AUTOSAR XML (schema 4-2-2)
package /STELLANTIS/EPT/ASWCs
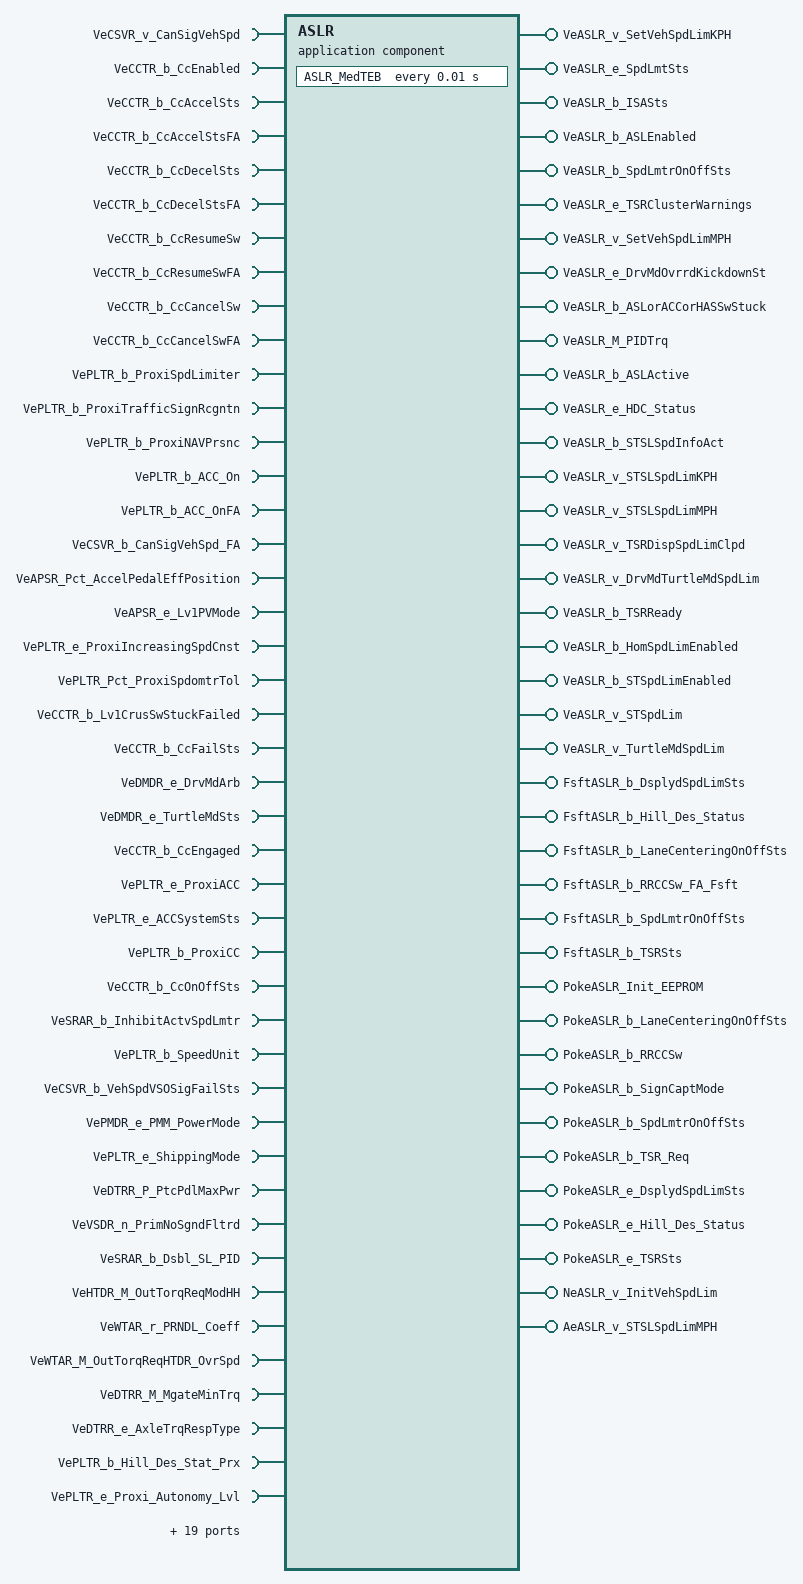
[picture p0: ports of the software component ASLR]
  application sw component type ASLR
    60 x require port:
      VeCSVR_v_CanSigVehSpd: variation-point={short-label=vpVeCSVR_v_CanSigVehSpd, sw-syscond=1}, nonqueued-receiver-com-spec{data-element=Value, init-value=0}, required-interface=VeCSVR_v_CanSigVehSpd
      VeCCTR_b_CcEnabled: variation-point={short-label=vpVeCCTR_b_CcEnabled, sw-syscond=1}, nonqueued-receiver-com-spec{data-element=Value, init-value=0}, required-interface=VeCCTR_b_CcEnabled
      VeCCTR_b_CcAccelSts: variation-point={short-label=vpVeCCTR_b_CcAccelSts, sw-syscond=1}, nonqueued-receiver-com-spec{data-element=Value, init-value=0}, required-interface=VeCCTR_b_CcAccelSts
      VeCCTR_b_CcAccelStsFA: variation-point={short-label=vpVeCCTR_b_CcAccelStsFA, sw-syscond=1}, nonqueued-receiver-com-spec{data-element=Value, init-value=0}, required-interface=VeCCTR_b_CcAccelStsFA
      VeCCTR_b_CcDecelSts: variation-point={short-label=vpVeCCTR_b_CcDecelSts, sw-syscond=1}, nonqueued-receiver-com-spec{data-element=Value, init-value=0}, required-interface=VeCCTR_b_CcDecelSts
      VeCCTR_b_CcDecelStsFA: variation-point={short-label=vpVeCCTR_b_CcDecelStsFA, sw-syscond=1}, nonqueued-receiver-com-spec{data-element=Value, init-value=0}, required-interface=VeCCTR_b_CcDecelStsFA
      VeCCTR_b_CcResumeSw: variation-point={short-label=vpVeCCTR_b_CcResumeSw, sw-syscond=1}, nonqueued-receiver-com-spec{data-element=Value, init-value=0}, required-interface=VeCCTR_b_CcResumeSw
      VeCCTR_b_CcResumeSwFA: variation-point={short-label=vpVeCCTR_b_CcResumeSwFA, sw-syscond=1}, nonqueued-receiver-com-spec{data-element=Value, init-value=0}, required-interface=VeCCTR_b_CcResumeSwFA
      VeCCTR_b_CcCancelSw: variation-point={short-label=vpVeCCTR_b_CcCancelSw, sw-syscond=1}, nonqueued-receiver-com-spec{data-element=Value, init-value=0}, required-interface=VeCCTR_b_CcCancelSw
      VeCCTR_b_CcCancelSwFA: variation-point={short-label=vpVeCCTR_b_CcCancelSwFA, sw-syscond=1}, nonqueued-receiver-com-spec{data-element=Value, init-value=0}, required-interface=VeCCTR_b_CcCancelSwFA
      VePLTR_b_ProxiSpdLimiter: variation-point={short-label=vpVePLTR_b_ProxiSpdLimiter, sw-syscond=1}, nonqueued-receiver-com-spec{data-element=Value, init-value=0}, required-interface=VePLTR_b_ProxiSpdLimiter
      VePLTR_b_ProxiTrafficSignRcgntn: variation-point={short-label=vpVePLTR_b_ProxiTrafficSignRcgntn, sw-syscond=1}, nonqueued-receiver-com-spec{data-element=Value, init-value=0}, required-interface=VePLTR_b_ProxiTrafficSignRcgntn
      VePLTR_b_ProxiNAVPrsnc: variation-point={short-label=vpVePLTR_b_ProxiNAVPrsnc, sw-syscond=1}, nonqueued-receiver-com-spec{data-element=Value, init-value=0}, required-interface=VePLTR_b_ProxiNAVPrsnc
      VePLTR_b_ACC_On: variation-point={short-label=vpVePLTR_b_ACC_On, sw-syscond=1}, nonqueued-receiver-com-spec{data-element=Value, init-value=0}, required-interface=VePLTR_b_ACC_On
      VePLTR_b_ACC_OnFA: variation-point={short-label=vpVePLTR_b_ACC_OnFA, sw-syscond=1}, nonqueued-receiver-com-spec{data-element=Value, init-value=0}, required-interface=VePLTR_b_ACC_OnFA
      VeCSVR_b_CanSigVehSpd_FA: variation-point={short-label=vpVeCSVR_b_CanSigVehSpd_FA, sw-syscond=1}, nonqueued-receiver-com-spec{data-element=Value, init-value=0}, required-interface=VeCSVR_b_CanSigVehSpd_FA
      VeAPSR_Pct_AccelPedalEffPosition: variation-point={short-label=vpVeAPSR_Pct_AccelPedalEffPosition, sw-syscond=1}, nonqueued-receiver-com-spec{data-element=Value, init-value=0}, required-interface=VeAPSR_Pct_AccelPedalEffPosition
      VeAPSR_e_Lv1PVMode: variation-point={short-label=vpVeAPSR_e_Lv1PVMode, sw-syscond=1}, nonqueued-receiver-com-spec{data-element=Value, init-value=CeAPSR_e_LV1PVMode_NotValid}, required-interface=VeAPSR_e_Lv1PVMode
      VePLTR_e_ProxiIncreasingSpdCnst: variation-point={short-label=vpVePLTR_e_ProxiIncreasingSpdCnst, sw-syscond=1}, nonqueued-receiver-com-spec{data-element=Value, init-value=CePLTR_e_Increasing_0}, required-interface=VePLTR_e_ProxiIncreasingSpdCnst
      VePLTR_Pct_ProxiSpdomtrTol: variation-point={short-label=vpVePLTR_Pct_ProxiSpdomtrTol, sw-syscond=1}, nonqueued-receiver-com-spec{data-element=Value, init-value=0}, required-interface=VePLTR_Pct_ProxiSpdomtrTol
      VeCCTR_b_Lv1CrusSwStuckFailed: variation-point={short-label=vpVeCCTR_b_Lv1CrusSwStuckFailed, sw-syscond=1}, nonqueued-receiver-com-spec{data-element=Value, init-value=0}, required-interface=VeCCTR_b_Lv1CrusSwStuckFailed
      VeCCTR_b_CcFailSts: variation-point={short-label=vpVeCCTR_b_CcFailSts, sw-syscond=1}, nonqueued-receiver-com-spec{data-element=Value, init-value=0}, required-interface=VeCCTR_b_CcFailSts
      VeDMDR_e_DrvMdArb: variation-point={short-label=vpVeDMDR_e_DrvMdArb, sw-syscond=1}, nonqueued-receiver-com-spec{data-element=Value, init-value=CeDMDR_e_NoDrvMd}, required-interface=VeDMDR_e_DrvMdArb
      VeDMDR_e_TurtleMdSts: variation-point={short-label=vpVeDMDR_e_TurtleMdSts, sw-syscond=1}, nonqueued-receiver-com-spec{data-element=Value, init-value=CeDMDR_e_No_Turtle_Mode}, required-interface=VeDMDR_e_TurtleMdSts
      VeCCTR_b_CcEngaged: variation-point={short-label=vpVeCCTR_b_CcEngaged, sw-syscond=1}, nonqueued-receiver-com-spec{data-element=Value, init-value=0}, required-interface=VeCCTR_b_CcEngaged
      VePLTR_e_ProxiACC: variation-point={short-label=vpVePLTR_e_ProxiACC, sw-syscond=1}, nonqueued-receiver-com-spec{data-element=Value, init-value=CePLTR_e_ACC_Absent}, required-interface=VePLTR_e_ProxiACC
      VePLTR_e_ACCSystemSts: variation-point={short-label=vpVePLTR_e_ACCSystemSts, sw-syscond=1}, nonqueued-receiver-com-spec{data-element=Value, init-value=CePLTR_e_Off}, required-interface=VePLTR_e_ACCSystemSts
      VePLTR_b_ProxiCC: variation-point={short-label=vpVePLTR_b_ProxiCC, sw-syscond=1}, nonqueued-receiver-com-spec{data-element=Value, init-value=0}, required-interface=VePLTR_b_ProxiCC
      VeCCTR_b_CcOnOffSts: variation-point={short-label=vpVeCCTR_b_CcOnOffSts, sw-syscond=1}, nonqueued-receiver-com-spec{data-element=Value, init-value=0}, required-interface=VeCCTR_b_CcOnOffSts
      VeSRAR_b_InhibitActvSpdLmtr: variation-point={short-label=vpVeSRAR_b_InhibitActvSpdLmtr, sw-syscond=1}, nonqueued-receiver-com-spec{data-element=Value, init-value=0}, required-interface=VeSRAR_b_InhibitActvSpdLmtr
      VePLTR_b_SpeedUnit: variation-point={short-label=vpVePLTR_b_SpeedUnit, sw-syscond=1}, nonqueued-receiver-com-spec{data-element=Value, init-value=0}, required-interface=VePLTR_b_SpeedUnit
      VeCSVR_b_VehSpdVSOSigFailSts: variation-point={short-label=vpVeCSVR_b_VehSpdVSOSigFailSts, sw-syscond=1}, nonqueued-receiver-com-spec{data-element=Value, init-value=0}, required-interface=VeCSVR_b_VehSpdVSOSigFailSts
      VePMDR_e_PMM_PowerMode: variation-point={short-label=vpVePMDR_e_PMM_PowerMode, sw-syscond=1}, nonqueued-receiver-com-spec{data-element=Value, init-value=CePMDR_e_PowerMode_Off}, required-interface=VePMDR_e_PMM_PowerMode
      VePLTR_e_ShippingMode: variation-point={short-label=vpVePLTR_e_ShippingMode, sw-syscond=1}, nonqueued-receiver-com-spec{data-element=Value, init-value=CePLTR_e_ShipingMode_CUST_MD}, required-interface=VePLTR_e_ShippingMode
      VeDTRR_P_PtcPdlMaxPwr: variation-point={short-label=vpVeDTRR_P_PtcPdlMaxPwr, sw-syscond=1}, nonqueued-receiver-com-spec{data-element=Value, init-value=0}, required-interface=VeDTRR_P_PtcPdlMaxPwr
      VeVSDR_n_PrimNoSgndFltrd: variation-point={short-label=vpVeVSDR_n_PrimNoSgndFltrd, sw-syscond=1}, nonqueued-receiver-com-spec{data-element=Value, init-value=0}, required-interface=VeVSDR_n_PrimNoSgndFltrd
      VeSRAR_b_Dsbl_SL_PID: variation-point={short-label=vpVeSRAR_b_Dsbl_SL_PID, sw-syscond=1}, nonqueued-receiver-com-spec{data-element=Value, init-value=0}, required-interface=VeSRAR_b_Dsbl_SL_PID
      VeHTDR_M_OutTorqReqModHH: variation-point={short-label=vpVeHTDR_M_OutTorqReqModHH, sw-syscond=1}, nonqueued-receiver-com-spec{data-element=Value, init-value=0}, required-interface=VeHTDR_M_OutTorqReqModHH
      VeWTAR_r_PRNDL_Coeff: variation-point={short-label=vpVeWTAR_r_PRNDL_Coeff, sw-syscond=1}, nonqueued-receiver-com-spec{data-element=Value, init-value=0}, required-interface=VeWTAR_r_PRNDL_Coeff
      VeWTAR_M_OutTorqReqHTDR_OvrSpd: variation-point={short-label=vpVeWTAR_M_OutTorqReqHTDR_OvrSpd, sw-syscond=1}, nonqueued-receiver-com-spec{data-element=Value, init-value=0}, required-interface=VeWTAR_M_OutTorqReqHTDR_OvrSpd
      VeDTRR_M_MgateMinTrq: variation-point={short-label=vpVeDTRR_M_MgateMinTrq, sw-syscond=1}, nonqueued-receiver-com-spec{data-element=Value, init-value=0}, required-interface=VeDTRR_M_MgateMinTrq
      VeDTRR_e_AxleTrqRespType: variation-point={short-label=vpVeDTRR_e_AxleTrqRespType, sw-syscond=1}, nonqueued-receiver-com-spec{data-element=Value, init-value=CePTAR_e_Inactive}, required-interface=VeDTRR_e_AxleTrqRespType
      VePLTR_b_Hill_Des_Stat_Prx: variation-point={short-label=vpVePLTR_b_Hill_Des_Stat_Prx, sw-syscond=1}, nonqueued-receiver-com-spec{data-element=Value, init-value=0}, required-interface=VePLTR_b_Hill_Des_Stat_Prx
      VePLTR_e_Proxi_Autonomy_Lvl: variation-point={short-label=vpVePLTR_e_Proxi_Autonomy_Lvl, sw-syscond=1}, nonqueued-receiver-com-spec{data-element=Value, init-value=CePLTR_e_None_Level1}, required-interface=VePLTR_e_Proxi_Autonomy_Lvl
      VePLTR_e_Proxi_CC_Logic: variation-point={short-label=vpVePLTR_e_Proxi_CC_Logic, sw-syscond=1}, nonqueued-receiver-com-spec{data-element=Value, init-value=CePLTR_e_Logic1}, required-interface=VePLTR_e_Proxi_CC_Logic
      VeTMDR_e_TrrnMd: variation-point={short-label=vpVeTMDR_e_TrrnMd, sw-syscond=1}, nonqueued-receiver-com-spec{data-element=Value, init-value=CeTMDR_e_NotDefine}, required-interface=VeTMDR_e_TrrnMd
      VeCCTR_b_CcFailStsFA: variation-point={short-label=vpVeCCTR_b_CcFailStsFA, sw-syscond=1}, nonqueued-receiver-com-spec{data-element=Value, init-value=0}, required-interface=VeCCTR_b_CcFailStsFA
      VePLTR_b_ACCSystemSts_FA: variation-point={short-label=vpVePLTR_b_ACCSystemSts_FA, sw-syscond=1}, nonqueued-receiver-com-spec{data-element=Value, init-value=0}, required-interface=VePLTR_b_ACCSystemSts_FA
      VePLTR_b_SpeedUnit_FA: variation-point={short-label=vpVePLTR_b_SpeedUnit_FA, sw-syscond=1}, nonqueued-receiver-com-spec{data-element=Value, init-value=0}, required-interface=VePLTR_b_SpeedUnit_FA
      VeCSVR_v_VehSpdSigned: variation-point={short-label=vpVeCSVR_v_VehSpdSigned, sw-syscond=1}, nonqueued-receiver-com-spec{data-element=Value, init-value=0}, required-interface=VeCSVR_v_VehSpdSigned
      VeBSWR_e_SpdLimEEProgStatus: variation-point={short-label=vpVeBSWR_e_SpdLimEEProgStatus, sw-syscond=1}, nonqueued-receiver-com-spec{data-element=Value, init-value=0}, required-interface=VeBSWR_e_SpdLimEEProgStatus
      VePMDR_e_OperationalModeSts: variation-point={short-label=vpVePMDR_e_OperationalModeSts, sw-syscond=1}, nonqueued-receiver-com-spec{data-element=Value, init-value=CePMDR_e_Init}, required-interface=VePMDR_e_OperationalModeSts
      VeDTRR_e_RrAxleTrqRespType: variation-point={short-label=vpVeDTRR_e_RrAxleTrqRespType, sw-syscond=1}, nonqueued-receiver-com-spec{data-element=Value, init-value=CePTAR_e_Inactive}, required-interface=VeDTRR_e_RrAxleTrqRespType
      VePLTR_v_HomSpdLim: variation-point={short-label=vpVePLTR_v_HomSpdLim, sw-syscond=1}, nonqueued-receiver-com-spec{data-element=Value, init-value=0}, required-interface=VePLTR_v_HomSpdLim
      VePLTR_b_HDCEnabledCAN: variation-point={short-label=vpVePLTR_b_HDCEnabledCAN, sw-syscond=1}, nonqueued-receiver-com-spec{data-element=Value, init-value=0}, required-interface=VePLTR_b_HDCEnabledCAN
      VePLTR_e_VehCategory: variation-point={short-label=vpVePLTR_e_VehCategory, sw-syscond=1}, nonqueued-receiver-com-spec{data-element=Value, init-value=CePLTR_e_Category_M1}, required-interface=VePLTR_e_VehCategory
      VePLTR_b_RRCCPROXI: variation-point={short-label=vpVePLTR_b_RRCCPROXI, sw-syscond=1}, nonqueued-receiver-com-spec{data-element=Value, init-value=0}, required-interface=VePLTR_b_RRCCPROXI
      VeTMDR_e_PropulsionMd: variation-point={short-label=vpVeTMDR_e_PropulsionMd, sw-syscond=1}, nonqueued-receiver-com-spec{data-element=Value, init-value=CeTMDR_e_NotDefine}, required-interface=VeTMDR_e_PropulsionMd
      VeDCAB_v_STSLSpdLimMPH_DidWrite: nonqueued-receiver-com-spec{data-element=Value, init-value=0}, required-interface=VeDCAB_v_STSLSpdLimMPH_DidWrite
      VeGRAR_b_DisableASL: variation-point={short-label=vpVeGRAR_b_DisableASL, sw-syscond=1}, nonqueued-receiver-com-spec{data-element=Value, init-value=0}, required-interface=VeGRAR_b_DisableASL
    37 x provide port:
      VeASLR_v_SetVehSpdLimKPH: nonqueued-sender-com-spec{data-element=Value, init-value=0}, provided-interface=VeASLR_v_SetVehSpdLimKPH
      VeASLR_e_SpdLmtSts: nonqueued-sender-com-spec{data-element=Value, init-value=0}, provided-interface=VeASLR_e_SpdLmtSts
      VeASLR_b_ISASts: nonqueued-sender-com-spec{data-element=Value, init-value=0}, provided-interface=VeASLR_b_ISASts
      VeASLR_b_ASLEnabled: nonqueued-sender-com-spec{data-element=Value, init-value=0}, provided-interface=VeASLR_b_ASLEnabled
      VeASLR_b_SpdLmtrOnOffSts: nonqueued-sender-com-spec{data-element=Value, init-value=0}, provided-interface=VeASLR_b_SpdLmtrOnOffSts
      VeASLR_e_TSRClusterWarnings: nonqueued-sender-com-spec{data-element=Value, init-value=0}, provided-interface=VeASLR_e_TSRClusterWarnings
      VeASLR_v_SetVehSpdLimMPH: nonqueued-sender-com-spec{data-element=Value, init-value=0}, provided-interface=VeASLR_v_SetVehSpdLimMPH
      VeASLR_e_DrvMdOvrrdKickdownSt: nonqueued-sender-com-spec{data-element=Value, init-value=0}, provided-interface=VeASLR_e_DrvMdOvrrdKickdownSt
      VeASLR_b_ASLorACCorHASSwStuck: nonqueued-sender-com-spec{data-element=Value, init-value=0}, provided-interface=VeASLR_b_ASLorACCorHASSwStuck
      VeASLR_M_PIDTrq: nonqueued-sender-com-spec{data-element=Value, init-value=0}, provided-interface=VeASLR_M_PIDTrq
      VeASLR_b_ASLActive: nonqueued-sender-com-spec{data-element=Value, init-value=0}, provided-interface=VeASLR_b_ASLActive
      VeASLR_e_HDC_Status: nonqueued-sender-com-spec{data-element=Value, init-value=CeASLR_e_HDC_UNAVL}, provided-interface=VeASLR_e_HDC_Status
      VeASLR_b_STSLSpdInfoAct: nonqueued-sender-com-spec{data-element=Value, init-value=0}, provided-interface=VeASLR_b_STSLSpdInfoAct
      VeASLR_v_STSLSpdLimKPH: nonqueued-sender-com-spec{data-element=Value, init-value=0}, provided-interface=VeASLR_v_STSLSpdLimKPH
      VeASLR_v_STSLSpdLimMPH: nonqueued-sender-com-spec{data-element=Value, init-value=0}, provided-interface=VeASLR_v_STSLSpdLimMPH
      VeASLR_v_TSRDispSpdLimClpd: nonqueued-sender-com-spec{data-element=Value, init-value=0}, provided-interface=VeASLR_v_TSRDispSpdLimClpd
      VeASLR_v_DrvMdTurtleMdSpdLim: nonqueued-sender-com-spec{data-element=Value, init-value=0}, provided-interface=VeASLR_v_DrvMdTurtleMdSpdLim
      VeASLR_b_TSRReady: nonqueued-sender-com-spec{data-element=Value, init-value=0}, provided-interface=VeASLR_b_TSRReady
      VeASLR_b_HomSpdLimEnabled: nonqueued-sender-com-spec{data-element=Value, init-value=0}, provided-interface=VeASLR_b_HomSpdLimEnabled
      VeASLR_b_STSpdLimEnabled: nonqueued-sender-com-spec{data-element=Value, init-value=0}, provided-interface=VeASLR_b_STSpdLimEnabled
      VeASLR_v_STSpdLim: nonqueued-sender-com-spec{data-element=Value, init-value=0}, provided-interface=VeASLR_v_STSpdLim
      VeASLR_v_TurtleMdSpdLim: nonqueued-sender-com-spec{data-element=Value, init-value=0}, provided-interface=VeASLR_v_TurtleMdSpdLim
      FsftASLR_b_DsplydSpdLimSts: server-com-spec=FsftASLR_b_DsplydSpdLimSts, provided-interface=FsftASLR_b_DsplydSpdLimSts
      FsftASLR_b_Hill_Des_Status: server-com-spec=FsftASLR_b_Hill_Des_Status, provided-interface=FsftASLR_b_Hill_Des_Status
      FsftASLR_b_LaneCenteringOnOffSts: server-com-spec=FsftASLR_b_LaneCenteringOnOffSts, provided-interface=FsftASLR_b_LaneCenteringOnOffSts
      FsftASLR_b_RRCCSw_FA_Fsft: server-com-spec=FsftASLR_b_RRCCSw_FA_Fsft, provided-interface=FsftASLR_b_RRCCSw_FA_Fsft
      FsftASLR_b_SpdLmtrOnOffSts: server-com-spec=FsftASLR_b_SpdLmtrOnOffSts, provided-interface=FsftASLR_b_SpdLmtrOnOffSts
      FsftASLR_b_TSRSts: server-com-spec=FsftASLR_b_TSRSts, provided-interface=FsftASLR_b_TSRSts
      PokeASLR_Init_EEPROM: server-com-spec=PokeASLR_Init_EEPROM, provided-interface=PokeASLR_Init_EEPROM
      PokeASLR_b_LaneCenteringOnOffSts: server-com-spec{operation=PokeASLR_b_LaneCenteringOnOffSts, queue-length=1}, provided-interface=PokeASLR_b_LaneCenteringOnOffSts
      PokeASLR_b_RRCCSw: server-com-spec{operation=PokeASLR_b_RRCCSw, queue-length=1}, provided-interface=PokeASLR_b_RRCCSw
      PokeASLR_b_SignCaptMode: server-com-spec{operation=PokeASLR_b_SignCaptMode, queue-length=1}, provided-interface=PokeASLR_b_SignCaptMode
      PokeASLR_b_SpdLmtrOnOffSts: server-com-spec{operation=PokeASLR_b_SpdLmtrOnOffSts, queue-length=1}, provided-interface=PokeASLR_b_SpdLmtrOnOffSts
      PokeASLR_b_TSR_Req: server-com-spec{operation=PokeASLR_b_TSR_Req, queue-length=1}, provided-interface=PokeASLR_b_TSR_Req
      PokeASLR_e_DsplydSpdLimSts: server-com-spec{operation=PokeASLR_e_DsplydSpdLimSts, queue-length=1}, provided-interface=PokeASLR_e_DsplydSpdLimSts
      PokeASLR_e_Hill_Des_Status: server-com-spec{operation=PokeASLR_e_Hill_Des_Status, queue-length=1}, provided-interface=PokeASLR_e_Hill_Des_Status
      PokeASLR_e_TSRSts: server-com-spec{operation=PokeASLR_e_TSRSts, queue-length=1}, provided-interface=PokeASLR_e_TSRSts
    require port NeASLR_v_InitVehSpdLim_Rx: nv-require-com-spec{init-value=0, variable=NeASLR_v_InitVehSpdLim}, required-interface=NeASLR_v_InitVehSpdLim
    require port AeASLR_v_STSLSpdLimMPH_Rx: nv-require-com-spec{init-value=0, variable=AeASLR_v_STSLSpdLimMPH}, required-interface=AeASLR_v_STSLSpdLimMPH
    provide port NeASLR_v_InitVehSpdLim: nv-provide-com-spec{ram-block-init-value=0, variable=NeASLR_v_InitVehSpdLim}, provided-interface=NeASLR_v_InitVehSpdLim
    provide port AeASLR_v_STSLSpdLimMPH: variation-point={short-label=vpAeASLR_v_STSLSpdLimMPH, sw-syscond=1}, nv-provide-com-spec{ram-block-init-value=0, variable=AeASLR_v_STSLSpdLimMPH}, provided-interface=AeASLR_v_STSLSpdLimMPH
    require port KeASLR_b_ASLInstantActivationEnable: parameter-require-com-spec{init-value=KeASLR_b_ASLInstantActivationEnable_KeASLR_b_ASLInstantActivationEnable:1, parameter=KeASLR_b_ASLInstantActivationEnable}, required-interface=KeASLR_b_ASLInstantActivationEnable
    behavior IB_ASLR: data-type-mapping=msADTtoIDTMapping, handle-termination-and-restart=NO-SUPPORT
      timing event Event_MedTEB: start-on-event=ASLR_MedTEB, period=0.01
      15 x operation invoked event:
        Event_FsftASLR_b_DsplydSpdLimSts: start-on-event=FsftASLR_b_DsplydSpdLimSts, operation=FsftASLR_b_DsplydSpdLimSts.FsftASLR_b_DsplydSpdLimSts
        Event_FsftASLR_b_Hill_Des_Status: start-on-event=FsftASLR_b_Hill_Des_Status, operation=FsftASLR_b_Hill_Des_Status.FsftASLR_b_Hill_Des_Status
        Event_FsftASLR_b_LaneCenteringOnOffSts: start-on-event=FsftASLR_b_LaneCenteringOnOffSts, operation=FsftASLR_b_LaneCenteringOnOffSts.FsftASLR_b_LaneCenteringOnOffSts
        Event_FsftASLR_b_RRCCSw_FA_Fsft: start-on-event=FsftASLR_b_RRCCSw_FA_Fsft, operation=FsftASLR_b_RRCCSw_FA_Fsft.FsftASLR_b_RRCCSw_FA_Fsft
        Event_FsftASLR_b_SpdLmtrOnOffSts: start-on-event=FsftASLR_b_SpdLmtrOnOffSts, operation=FsftASLR_b_SpdLmtrOnOffSts.FsftASLR_b_SpdLmtrOnOffSts
        Event_FsftASLR_b_TSRSts: start-on-event=FsftASLR_b_TSRSts, operation=FsftASLR_b_TSRSts.FsftASLR_b_TSRSts
        Event_PokeASLR_Init_EEPROM: start-on-event=PokeASLR_Init_EEPROM, operation=PokeASLR_Init_EEPROM.PokeASLR_Init_EEPROM
        Event_PokeASLR_b_LaneCenteringOnOffSts: start-on-event=PokeASLR_b_LaneCenteringOnOffSts, operation=PokeASLR_b_LaneCenteringOnOffSts.PokeASLR_b_LaneCenteringOnOffSts
        Event_PokeASLR_b_RRCCSw: start-on-event=PokeASLR_b_RRCCSw, operation=PokeASLR_b_RRCCSw.PokeASLR_b_RRCCSw
        Event_PokeASLR_b_SignCaptMode: start-on-event=PokeASLR_b_SignCaptMode, operation=PokeASLR_b_SignCaptMode.PokeASLR_b_SignCaptMode
        Event_PokeASLR_b_SpdLmtrOnOffSts: start-on-event=PokeASLR_b_SpdLmtrOnOffSts, operation=PokeASLR_b_SpdLmtrOnOffSts.PokeASLR_b_SpdLmtrOnOffSts
        Event_PokeASLR_b_TSR_Req: start-on-event=PokeASLR_b_TSR_Req, operation=PokeASLR_b_TSR_Req.PokeASLR_b_TSR_Req
        Event_PokeASLR_e_DsplydSpdLimSts: start-on-event=PokeASLR_e_DsplydSpdLimSts, operation=PokeASLR_e_DsplydSpdLimSts.PokeASLR_e_DsplydSpdLimSts
        Event_PokeASLR_e_Hill_Des_Status: start-on-event=PokeASLR_e_Hill_Des_Status, operation=PokeASLR_e_Hill_Des_Status.PokeASLR_e_Hill_Des_Status
        Event_PokeASLR_e_TSRSts: start-on-event=PokeASLR_e_TSRSts, operation=PokeASLR_e_TSRSts.PokeASLR_e_TSRSts
      init event Event_ASLR_ac_Init: start-on-event=ASLR_ac_Init
      init event Event_PwrOn: start-on-event=ASLR_PwrOn
      init event Event_PwrOff: start-on-event=ASLR_PwrOff
      data received event Event_DIDWrite_RWDB61B_SERVICETOOLSPEED: start-on-event=DIDWrite_RWDB61B_SERVICETOOLSPEED, data=VeDCAB_v_STSLSpdLimMPH_DidWrite.Value
      explicit-inter-runnable-variables:
        14 x data, all with category=VALUE, sw-calibration-access=READ-ONLY:
          TSRSts_write_IRV: type=TeASLR_e_TSRSts, init-value=CeASLR_e_TSRNotActive
          SpeedLimiterOnOffSts_write_IRV: type=Boolean, init-value=0
          DisplayedSpeedLimSts_write_IRV: type=SInt16, init-value=0
          SignCaptureMode_write_IRV: type=Boolean, init-value=0
          SpeedLimiterOnOffStsFA_write_IRV: type=Boolean, init-value=0
          LaneCenteringOnOffSts_write_IRV: type=Boolean, init-value=0
          LaneCenteringOnOffStsFA_write_IRV: type=Boolean, init-value=0
          TSR_Req_write_IRV: type=Boolean, init-value=0
          Hill_Des_St_Init_write_IRV: type=TeASLR_e_HDC_Status, init-value=CeASLR_e_HDC_UNAVL
          HDC_FA_Init_write_IRV: type=Boolean, init-value=0
          TSRStsFA_Init_write_IRV: type=Boolean, init-value=0
          DsplydSpdLimStsFA_Init_write_IRV: type=Boolean, init-value=0
          RRCCSW_Init_write_IRV: type=SInt16, init-value=0
          RRCCSW_FA_Init_write_IRV: type=Boolean, init-value=0
      20 x runnable:
        ASLR_ac_Init
          data-send-points:
            access OUT_VeASLR_e_HDC_Status_Value: accessed-variable=VeASLR_e_HDC_Status.Value
        ASLR_PwrOn
          data-receive-point-by-arguments:
            access IN_AeASLR_v_STSLSpdLimMPH_Rx_AeASLR_v_STSLSpdLimMPH: accessed-variable=AeASLR_v_STSLSpdLimMPH_Rx.AeASLR_v_STSLSpdLimMPH
            access IN_NeASLR_v_InitVehSpdLim_Rx_NeASLR_v_InitVehSpdLim: accessed-variable=NeASLR_v_InitVehSpdLim_Rx.NeASLR_v_InitVehSpdLim
          data-send-points:
            22 x access:
              OUT_VeASLR_v_SetVehSpdLimKPH_Value: accessed-variable=VeASLR_v_SetVehSpdLimKPH.Value
              OUT_VeASLR_e_SpdLmtSts_Value: accessed-variable=VeASLR_e_SpdLmtSts.Value
              OUT_VeASLR_b_ASLActive_Value: accessed-variable=VeASLR_b_ASLActive.Value
              OUT_VeASLR_e_HDC_Status_Value: accessed-variable=VeASLR_e_HDC_Status.Value
              OUT_VeASLR_b_STSLSpdInfoAct_Value: accessed-variable=VeASLR_b_STSLSpdInfoAct.Value
              OUT_VeASLR_v_STSLSpdLimKPH_Value: accessed-variable=VeASLR_v_STSLSpdLimKPH.Value
              OUT_VeASLR_v_STSLSpdLimMPH_Value: accessed-variable=VeASLR_v_STSLSpdLimMPH.Value
              OUT_VeASLR_v_TSRDispSpdLimClpd_Value: accessed-variable=VeASLR_v_TSRDispSpdLimClpd.Value
              OUT_VeASLR_v_DrvMdTurtleMdSpdLim_Value: accessed-variable=VeASLR_v_DrvMdTurtleMdSpdLim.Value
              OUT_VeASLR_b_TSRReady_Value: accessed-variable=VeASLR_b_TSRReady.Value
              OUT_VeASLR_b_HomSpdLimEnabled_Value: accessed-variable=VeASLR_b_HomSpdLimEnabled.Value
              OUT_VeASLR_b_STSpdLimEnabled_Value: accessed-variable=VeASLR_b_STSpdLimEnabled.Value
              OUT_VeASLR_b_ISASts_Value: accessed-variable=VeASLR_b_ISASts.Value
              OUT_VeASLR_v_STSpdLim_Value: accessed-variable=VeASLR_v_STSpdLim.Value
              OUT_VeASLR_b_ASLEnabled_Value: accessed-variable=VeASLR_b_ASLEnabled.Value
              OUT_VeASLR_e_TSRClusterWarnings_Value: accessed-variable=VeASLR_e_TSRClusterWarnings.Value
              OUT_VeASLR_v_SetVehSpdLimMPH_Value: accessed-variable=VeASLR_v_SetVehSpdLimMPH.Value
              OUT_VeASLR_e_DrvMdOvrrdKickdownSt_Value: accessed-variable=VeASLR_e_DrvMdOvrrdKickdownSt.Value
              OUT_VeASLR_b_SpdLmtrOnOffSts_Value: accessed-variable=VeASLR_b_SpdLmtrOnOffSts.Value
              OUT_VeASLR_b_ASLorACCorHASSwStuck_Value: accessed-variable=VeASLR_b_ASLorACCorHASSwStuck.Value
              OUT_VeASLR_M_PIDTrq_Value: accessed-variable=VeASLR_M_PIDTrq.Value
              OUT_VeASLR_v_TurtleMdSpdLim_Value: accessed-variable=VeASLR_v_TurtleMdSpdLim.Value
          written-local-variables:
            14 x access:
              WV_DisplayedSpeedLimSts_write_IRV: accessed-variable=DisplayedSpeedLimSts_write_IRV
              WV_DsplydSpdLimStsFA_Init_write_IRV: accessed-variable=DsplydSpdLimStsFA_Init_write_IRV
              WV_HDC_FA_Init_write_IRV: accessed-variable=HDC_FA_Init_write_IRV
              WV_Hill_Des_St_Init_write_IRV: accessed-variable=Hill_Des_St_Init_write_IRV
              WV_LaneCenteringOnOffStsFA_write_IRV: accessed-variable=LaneCenteringOnOffStsFA_write_IRV
              WV_LaneCenteringOnOffSts_write_IRV: accessed-variable=LaneCenteringOnOffSts_write_IRV
              WV_RRCCSW_FA_Init_write_IRV: accessed-variable=RRCCSW_FA_Init_write_IRV
              WV_RRCCSW_Init_write_IRV: accessed-variable=RRCCSW_Init_write_IRV
              WV_SignCaptureMode_write_IRV: accessed-variable=SignCaptureMode_write_IRV
              WV_SpeedLimiterOnOffStsFA_write_IRV: accessed-variable=SpeedLimiterOnOffStsFA_write_IRV
              WV_SpeedLimiterOnOffSts_write_IRV: accessed-variable=SpeedLimiterOnOffSts_write_IRV
              WV_TSRStsFA_Init_write_IRV: accessed-variable=TSRStsFA_Init_write_IRV
              WV_TSRSts_write_IRV: accessed-variable=TSRSts_write_IRV
              WV_TSR_Req_write_IRV: accessed-variable=TSR_Req_write_IRV
        ASLR_MedTEB: variation-point={short-label=vpASLR_MedTEB, sw-syscond=1}
          data-receive-point-by-arguments:
            59 x access:
              IN_VeAPSR_Pct_AccelPedalEffPosition_Value: accessed-variable=VeAPSR_Pct_AccelPedalEffPosition.Value, variation-point={short-label=vpIN_VeAPSR_Pct_AccelPedalEffPosition_Value, sw-syscond=1}
              IN_VeAPSR_e_Lv1PVMode_Value: accessed-variable=VeAPSR_e_Lv1PVMode.Value, variation-point={short-label=vpIN_VeAPSR_e_Lv1PVMode_Value, sw-syscond=1}
              IN_VeBSWR_e_SpdLimEEProgStatus_Value: accessed-variable=VeBSWR_e_SpdLimEEProgStatus.Value, variation-point={short-label=vpIN_VeBSWR_e_SpdLimEEProgStatus_Value, sw-syscond=1}
              IN_VeCCTR_b_CcAccelSts_Value: accessed-variable=VeCCTR_b_CcAccelSts.Value, variation-point={short-label=vpIN_VeCCTR_b_CcAccelSts_Value, sw-syscond=1}
              IN_VeCCTR_b_CcAccelStsFA_Value: accessed-variable=VeCCTR_b_CcAccelStsFA.Value, variation-point={short-label=vpIN_VeCCTR_b_CcAccelStsFA_Value, sw-syscond=1}
              IN_VeCCTR_b_CcCancelSw_Value: accessed-variable=VeCCTR_b_CcCancelSw.Value, variation-point={short-label=vpIN_VeCCTR_b_CcCancelSw_Value, sw-syscond=1}
              IN_VeCCTR_b_CcCancelSwFA_Value: accessed-variable=VeCCTR_b_CcCancelSwFA.Value, variation-point={short-label=vpIN_VeCCTR_b_CcCancelSwFA_Value, sw-syscond=1}
              IN_VeCCTR_b_CcDecelSts_Value: accessed-variable=VeCCTR_b_CcDecelSts.Value, variation-point={short-label=vpIN_VeCCTR_b_CcDecelSts_Value, sw-syscond=1}
              IN_VeCCTR_b_CcDecelStsFA_Value: accessed-variable=VeCCTR_b_CcDecelStsFA.Value, variation-point={short-label=vpIN_VeCCTR_b_CcDecelStsFA_Value, sw-syscond=1}
              IN_VeCCTR_b_CcEnabled_Value: accessed-variable=VeCCTR_b_CcEnabled.Value, variation-point={short-label=vpIN_VeCCTR_b_CcEnabled_Value, sw-syscond=1}
              IN_VeCCTR_b_CcEngaged_Value: accessed-variable=VeCCTR_b_CcEngaged.Value, variation-point={short-label=vpIN_VeCCTR_b_CcEngaged_Value, sw-syscond=1}
              IN_VeCCTR_b_CcFailSts_Value: accessed-variable=VeCCTR_b_CcFailSts.Value, variation-point={short-label=vpIN_VeCCTR_b_CcFailSts_Value, sw-syscond=1}
              IN_VeCCTR_b_CcFailStsFA_Value: accessed-variable=VeCCTR_b_CcFailStsFA.Value, variation-point={short-label=vpIN_VeCCTR_b_CcFailStsFA_Value, sw-syscond=1}
              IN_VeCCTR_b_CcOnOffSts_Value: accessed-variable=VeCCTR_b_CcOnOffSts.Value, variation-point={short-label=vpIN_VeCCTR_b_CcOnOffSts_Value, sw-syscond=1}
              IN_VeCCTR_b_CcResumeSw_Value: accessed-variable=VeCCTR_b_CcResumeSw.Value, variation-point={short-label=vpIN_VeCCTR_b_CcResumeSw_Value, sw-syscond=1}
              IN_VeCCTR_b_CcResumeSwFA_Value: accessed-variable=VeCCTR_b_CcResumeSwFA.Value, variation-point={short-label=vpIN_VeCCTR_b_CcResumeSwFA_Value, sw-syscond=1}
              IN_VeCCTR_b_Lv1CrusSwStuckFailed_Value: accessed-variable=VeCCTR_b_Lv1CrusSwStuckFailed.Value, variation-point={short-label=vpIN_VeCCTR_b_Lv1CrusSwStuckFailed_Value, sw-syscond=1}
              IN_VeCSVR_b_CanSigVehSpd_FA_Value: accessed-variable=VeCSVR_b_CanSigVehSpd_FA.Value, variation-point={short-label=vpIN_VeCSVR_b_CanSigVehSpd_FA_Value, sw-syscond=1}
              IN_VeCSVR_b_VehSpdVSOSigFailSts_Value: accessed-variable=VeCSVR_b_VehSpdVSOSigFailSts.Value, variation-point={short-label=vpIN_VeCSVR_b_VehSpdVSOSigFailSts_Value, sw-syscond=1}
              IN_VeCSVR_v_CanSigVehSpd_Value: accessed-variable=VeCSVR_v_CanSigVehSpd.Value, variation-point={short-label=vpIN_VeCSVR_v_CanSigVehSpd_Value, sw-syscond=1}
              IN_VeCSVR_v_VehSpdSigned_Value: accessed-variable=VeCSVR_v_VehSpdSigned.Value, variation-point={short-label=vpIN_VeCSVR_v_VehSpdSigned_Value, sw-syscond=1}
              IN_VeDMDR_e_DrvMdArb_Value: accessed-variable=VeDMDR_e_DrvMdArb.Value, variation-point={short-label=vpIN_VeDMDR_e_DrvMdArb_Value, sw-syscond=1}
              IN_VeDMDR_e_TurtleMdSts_Value: accessed-variable=VeDMDR_e_TurtleMdSts.Value, variation-point={short-label=vpIN_VeDMDR_e_TurtleMdSts_Value, sw-syscond=1}
              IN_VeDTRR_M_MgateMinTrq_Value: accessed-variable=VeDTRR_M_MgateMinTrq.Value, variation-point={short-label=vpIN_VeDTRR_M_MgateMinTrq_Value, sw-syscond=1}
              IN_VeDTRR_P_PtcPdlMaxPwr_Value: accessed-variable=VeDTRR_P_PtcPdlMaxPwr.Value, variation-point={short-label=vpIN_VeDTRR_P_PtcPdlMaxPwr_Value, sw-syscond=1}
              IN_VeDTRR_e_AxleTrqRespType_Value: accessed-variable=VeDTRR_e_AxleTrqRespType.Value, variation-point={short-label=vpIN_VeDTRR_e_AxleTrqRespType_Value, sw-syscond=1}
              IN_VeDTRR_e_RrAxleTrqRespType_Value: accessed-variable=VeDTRR_e_RrAxleTrqRespType.Value, variation-point={short-label=vpIN_VeDTRR_e_RrAxleTrqRespType_Value, sw-syscond=1}
              IN_VeGRAR_b_DisableASL_Value: accessed-variable=VeGRAR_b_DisableASL.Value, variation-point={short-label=vpIN_VeGRAR_b_DisableASL_Value, sw-syscond=1}
              IN_VeHTDR_M_OutTorqReqModHH_Value: accessed-variable=VeHTDR_M_OutTorqReqModHH.Value, variation-point={short-label=vpIN_VeHTDR_M_OutTorqReqModHH_Value, sw-syscond=1}
              IN_VePLTR_Pct_ProxiSpdomtrTol_Value: accessed-variable=VePLTR_Pct_ProxiSpdomtrTol.Value, variation-point={short-label=vpIN_VePLTR_Pct_ProxiSpdomtrTol_Value, sw-syscond=1}
              IN_VePLTR_b_ACCSystemSts_FA_Value: accessed-variable=VePLTR_b_ACCSystemSts_FA.Value, variation-point={short-label=vpIN_VePLTR_b_ACCSystemSts_FA_Value, sw-syscond=1}
              IN_VePLTR_b_ACC_On_Value: accessed-variable=VePLTR_b_ACC_On.Value, variation-point={short-label=vpIN_VePLTR_b_ACC_On_Value, sw-syscond=1}
              IN_VePLTR_b_ACC_OnFA_Value: accessed-variable=VePLTR_b_ACC_OnFA.Value, variation-point={short-label=vpIN_VePLTR_b_ACC_OnFA_Value, sw-syscond=1}
              IN_VePLTR_b_HDCEnabledCAN_Value: accessed-variable=VePLTR_b_HDCEnabledCAN.Value, variation-point={short-label=vpIN_VePLTR_b_HDCEnabledCAN_Value, sw-syscond=1}
              IN_VePLTR_b_Hill_Des_Stat_Prx_Value: accessed-variable=VePLTR_b_Hill_Des_Stat_Prx.Value, variation-point={short-label=vpIN_VePLTR_b_Hill_Des_Stat_Prx_Value, sw-syscond=1}
              IN_VePLTR_b_ProxiCC_Value: accessed-variable=VePLTR_b_ProxiCC.Value, variation-point={short-label=vpIN_VePLTR_b_ProxiCC_Value, sw-syscond=1}
              IN_VePLTR_b_ProxiNAVPrsnc_Value: accessed-variable=VePLTR_b_ProxiNAVPrsnc.Value, variation-point={short-label=vpIN_VePLTR_b_ProxiNAVPrsnc_Value, sw-syscond=1}
              IN_VePLTR_b_ProxiSpdLimiter_Value: accessed-variable=VePLTR_b_ProxiSpdLimiter.Value, variation-point={short-label=vpIN_VePLTR_b_ProxiSpdLimiter_Value, sw-syscond=1}
              IN_VePLTR_b_ProxiTrafficSignRcgntn_Value: accessed-variable=VePLTR_b_ProxiTrafficSignRcgntn.Value, variation-point={short-label=vpIN_VePLTR_b_ProxiTrafficSignRcgntn_Value, sw-syscond=1}
              IN_VePLTR_b_RRCCPROXI_Value: accessed-variable=VePLTR_b_RRCCPROXI.Value, variation-point={short-label=vpIN_VePLTR_b_RRCCPROXI_Value, sw-syscond=1}
              IN_VePLTR_b_SpeedUnit_Value: accessed-variable=VePLTR_b_SpeedUnit.Value, variation-point={short-label=vpIN_VePLTR_b_SpeedUnit_Value, sw-syscond=1}
              IN_VePLTR_b_SpeedUnit_FA_Value: accessed-variable=VePLTR_b_SpeedUnit_FA.Value, variation-point={short-label=vpIN_VePLTR_b_SpeedUnit_FA_Value, sw-syscond=1}
              IN_VePLTR_e_ACCSystemSts_Value: accessed-variable=VePLTR_e_ACCSystemSts.Value, variation-point={short-label=vpIN_VePLTR_e_ACCSystemSts_Value, sw-syscond=1}
              IN_VePLTR_e_ProxiACC_Value: accessed-variable=VePLTR_e_ProxiACC.Value, variation-point={short-label=vpIN_VePLTR_e_ProxiACC_Value, sw-syscond=1}
              IN_VePLTR_e_ProxiIncreasingSpdCnst_Value: accessed-variable=VePLTR_e_ProxiIncreasingSpdCnst.Value, variation-point={short-label=vpIN_VePLTR_e_ProxiIncreasingSpdCnst_Value, sw-syscond=1}
              IN_VePLTR_e_Proxi_Autonomy_Lvl_Value: accessed-variable=VePLTR_e_Proxi_Autonomy_Lvl.Value, variation-point={short-label=vpIN_VePLTR_e_Proxi_Autonomy_Lvl_Value, sw-syscond=1}
              IN_VePLTR_e_Proxi_CC_Logic_Value: accessed-variable=VePLTR_e_Proxi_CC_Logic.Value, variation-point={short-label=vpIN_VePLTR_e_Proxi_CC_Logic_Value, sw-syscond=1}
              IN_VePLTR_e_ShippingMode_Value: accessed-variable=VePLTR_e_ShippingMode.Value, variation-point={short-label=vpIN_VePLTR_e_ShippingMode_Value, sw-syscond=1}
              IN_VePLTR_e_VehCategory_Value: accessed-variable=VePLTR_e_VehCategory.Value, variation-point={short-label=vpIN_VePLTR_e_VehCategory_Value, sw-syscond=1}
              IN_VePLTR_v_HomSpdLim_Value: accessed-variable=VePLTR_v_HomSpdLim.Value, variation-point={short-label=vpIN_VePLTR_v_HomSpdLim_Value, sw-syscond=1}
              IN_VePMDR_e_OperationalModeSts_Value: accessed-variable=VePMDR_e_OperationalModeSts.Value, variation-point={short-label=vpIN_VePMDR_e_OperationalModeSts_Value, sw-syscond=1}
              IN_VePMDR_e_PMM_PowerMode_Value: accessed-variable=VePMDR_e_PMM_PowerMode.Value, variation-point={short-label=vpIN_VePMDR_e_PMM_PowerMode_Value, sw-syscond=1}
              IN_VeSRAR_b_Dsbl_SL_PID_Value: accessed-variable=VeSRAR_b_Dsbl_SL_PID.Value, variation-point={short-label=vpIN_VeSRAR_b_Dsbl_SL_PID_Value, sw-syscond=1}
              IN_VeSRAR_b_InhibitActvSpdLmtr_Value: accessed-variable=VeSRAR_b_InhibitActvSpdLmtr.Value, variation-point={short-label=vpIN_VeSRAR_b_InhibitActvSpdLmtr_Value, sw-syscond=1}
              IN_VeTMDR_e_PropulsionMd_Value: accessed-variable=VeTMDR_e_PropulsionMd.Value, variation-point={short-label=vpIN_VeTMDR_e_PropulsionMd_Value, sw-syscond=1}
              IN_VeTMDR_e_TrrnMd_Value: accessed-variable=VeTMDR_e_TrrnMd.Value, variation-point={short-label=vpIN_VeTMDR_e_TrrnMd_Value, sw-syscond=1}
              IN_VeVSDR_n_PrimNoSgndFltrd_Value: accessed-variable=VeVSDR_n_PrimNoSgndFltrd.Value, variation-point={short-label=vpIN_VeVSDR_n_PrimNoSgndFltrd_Value, sw-syscond=1}
              IN_VeWTAR_M_OutTorqReqHTDR_OvrSpd_Value: accessed-variable=VeWTAR_M_OutTorqReqHTDR_OvrSpd.Value, variation-point={short-label=vpIN_VeWTAR_M_OutTorqReqHTDR_OvrSpd_Value, sw-syscond=1}
              IN_VeWTAR_r_PRNDL_Coeff_Value: accessed-variable=VeWTAR_r_PRNDL_Coeff.Value, variation-point={short-label=vpIN_VeWTAR_r_PRNDL_Coeff_Value, sw-syscond=1}
          data-send-points:
            23 x access:
              OUT_VeASLR_v_SetVehSpdLimKPH_Value: accessed-variable=VeASLR_v_SetVehSpdLimKPH.Value
              OUT_VeASLR_e_SpdLmtSts_Value: accessed-variable=VeASLR_e_SpdLmtSts.Value
              OUT_VeASLR_b_ASLActive_Value: accessed-variable=VeASLR_b_ASLActive.Value
              OUT_VeASLR_e_HDC_Status_Value: accessed-variable=VeASLR_e_HDC_Status.Value
              OUT_VeASLR_b_STSLSpdInfoAct_Value: accessed-variable=VeASLR_b_STSLSpdInfoAct.Value
              OUT_VeASLR_v_STSLSpdLimKPH_Value: accessed-variable=VeASLR_v_STSLSpdLimKPH.Value
              OUT_VeASLR_v_STSLSpdLimMPH_Value: accessed-variable=VeASLR_v_STSLSpdLimMPH.Value
              OUT_VeASLR_v_TSRDispSpdLimClpd_Value: accessed-variable=VeASLR_v_TSRDispSpdLimClpd.Value
              OUT_VeASLR_v_DrvMdTurtleMdSpdLim_Value: accessed-variable=VeASLR_v_DrvMdTurtleMdSpdLim.Value
              OUT_VeASLR_b_TSRReady_Value: accessed-variable=VeASLR_b_TSRReady.Value
              OUT_VeASLR_b_HomSpdLimEnabled_Value: accessed-variable=VeASLR_b_HomSpdLimEnabled.Value
              OUT_VeASLR_b_STSpdLimEnabled_Value: accessed-variable=VeASLR_b_STSpdLimEnabled.Value
              OUT_VeASLR_b_ISASts_Value: accessed-variable=VeASLR_b_ISASts.Value
              OUT_VeASLR_v_STSpdLim_Value: accessed-variable=VeASLR_v_STSpdLim.Value
              OUT_VeASLR_b_ASLEnabled_Value: accessed-variable=VeASLR_b_ASLEnabled.Value
              OUT_VeASLR_e_TSRClusterWarnings_Value: accessed-variable=VeASLR_e_TSRClusterWarnings.Value
              OUT_VeASLR_v_SetVehSpdLimMPH_Value: accessed-variable=VeASLR_v_SetVehSpdLimMPH.Value
              OUT_VeASLR_e_DrvMdOvrrdKickdownSt_Value: accessed-variable=VeASLR_e_DrvMdOvrrdKickdownSt.Value
              OUT_VeASLR_b_SpdLmtrOnOffSts_Value: accessed-variable=VeASLR_b_SpdLmtrOnOffSts.Value
              OUT_VeASLR_b_ASLorACCorHASSwStuck_Value: accessed-variable=VeASLR_b_ASLorACCorHASSwStuck.Value
              OUT_VeASLR_M_PIDTrq_Value: accessed-variable=VeASLR_M_PIDTrq.Value
              OUT_AeASLR_v_STSLSpdLimMPH_AeASLR_v_STSLSpdLimMPH: accessed-variable=AeASLR_v_STSLSpdLimMPH.AeASLR_v_STSLSpdLimMPH, variation-point={short-label=vpOUT_AeASLR_v_STSLSpdLimMPH_AeASLR_v_STSLSpdLimMPH, sw-syscond=1}
              OUT_VeASLR_v_TurtleMdSpdLim_Value: accessed-variable=VeASLR_v_TurtleMdSpdLim.Value
          parameter access CALPRM_KeASLR_b_ASLInstantActivationEnable_KeASLR_b_ASLInstantActivationEnable: accessed-parameter=KeASLR_b_ASLInstantActivationEnable.KeASLR_b_ASLInstantActivationEnable, variation-point={short-label=vpCALPRM_KeASLR_b_ASLInstantActivationEnable_KeASLR_b_ASLInstantActivationEnable, sw-syscond=1}
          read-local-variables:
            13 x access:
              RV_DisplayedSpeedLimSts_write_IRV: accessed-variable=DisplayedSpeedLimSts_write_IRV, variation-point={short-label=vpRV_DisplayedSpeedLimSts_write_IRV, sw-syscond=1}
              RV_DsplydSpdLimStsFA_Init_write_IRV: accessed-variable=DsplydSpdLimStsFA_Init_write_IRV, variation-point={short-label=vpRV_DsplydSpdLimStsFA_Init_write_IRV, sw-syscond=1}
              RV_HDC_FA_Init_write_IRV: accessed-variable=HDC_FA_Init_write_IRV, variation-point={short-label=vpRV_HDC_FA_Init_write_IRV, sw-syscond=1}
              RV_Hill_Des_St_Init_write_IRV: accessed-variable=Hill_Des_St_Init_write_IRV, variation-point={short-label=vpRV_Hill_Des_St_Init_write_IRV, sw-syscond=1}
              RV_LaneCenteringOnOffStsFA_write_IRV: accessed-variable=LaneCenteringOnOffStsFA_write_IRV, variation-point={short-label=vpRV_LaneCenteringOnOffStsFA_write_IRV, sw-syscond=1}
              RV_LaneCenteringOnOffSts_write_IRV: accessed-variable=LaneCenteringOnOffSts_write_IRV, variation-point={short-label=vpRV_LaneCenteringOnOffSts_write_IRV, sw-syscond=1}
              RV_RRCCSW_Init_write_IRV: accessed-variable=RRCCSW_Init_write_IRV, variation-point={short-label=vpRV_RRCCSW_Init_write_IRV, sw-syscond=1}
              RV_SignCaptureMode_write_IRV: accessed-variable=SignCaptureMode_write_IRV, variation-point={short-label=vpRV_SignCaptureMode_write_IRV, sw-syscond=1}
              RV_SpeedLimiterOnOffStsFA_write_IRV: accessed-variable=SpeedLimiterOnOffStsFA_write_IRV, variation-point={short-label=vpRV_SpeedLimiterOnOffStsFA_write_IRV, sw-syscond=1}
              RV_SpeedLimiterOnOffSts_write_IRV: accessed-variable=SpeedLimiterOnOffSts_write_IRV, variation-point={short-label=vpRV_SpeedLimiterOnOffSts_write_IRV, sw-syscond=1}
              RV_TSRStsFA_Init_write_IRV: accessed-variable=TSRStsFA_Init_write_IRV, variation-point={short-label=vpRV_TSRStsFA_Init_write_IRV, sw-syscond=1}
              RV_TSRSts_write_IRV: accessed-variable=TSRSts_write_IRV, variation-point={short-label=vpRV_TSRSts_write_IRV, sw-syscond=1}
              RV_TSR_Req_write_IRV: accessed-variable=TSR_Req_write_IRV, variation-point={short-label=vpRV_TSR_Req_write_IRV, sw-syscond=1}
        ASLR_PwrOff
          data-send-points:
            access OUT_NeASLR_v_InitVehSpdLim_NeASLR_v_InitVehSpdLim: accessed-variable=NeASLR_v_InitVehSpdLim.NeASLR_v_InitVehSpdLim
        DIDWrite_RWDB61B_SERVICETOOLSPEED
          data-receive-point-by-arguments:
            access IN_VeDCAB_v_STSLSpdLimMPH_DidWrite_Value: accessed-variable=VeDCAB_v_STSLSpdLimMPH_DidWrite.Value
        FsftASLR_b_DsplydSpdLimSts: variation-point={short-label=vpFsftASLR_b_DsplydSpdLimSts, sw-syscond=1}
          written-local-variables:
            access WV_DsplydSpdLimStsFA_Init_write_IRV: accessed-variable=DsplydSpdLimStsFA_Init_write_IRV, variation-point={short-label=vpWV_DsplydSpdLimStsFA_Init_write_IRV, sw-syscond=1}
        FsftASLR_b_Hill_Des_Status: variation-point={short-label=vpFsftASLR_b_Hill_Des_Status, sw-syscond=1}
          written-local-variables:
            access WV_HDC_FA_Init_write_IRV: accessed-variable=HDC_FA_Init_write_IRV, variation-point={short-label=vpWV_HDC_FA_Init_write_IRV, sw-syscond=1}
        FsftASLR_b_LaneCenteringOnOffSts: variation-point={short-label=vpFsftASLR_b_LaneCenteringOnOffSts, sw-syscond=1}
          written-local-variables:
            access WV_LaneCenteringOnOffStsFA_write_IRV: accessed-variable=LaneCenteringOnOffStsFA_write_IRV, variation-point={short-label=vpWV_LaneCenteringOnOffStsFA_write_IRV, sw-syscond=1}
        FsftASLR_b_RRCCSw_FA_Fsft: variation-point={short-label=vpFsftASLR_b_RRCCSw_FA_Fsft, sw-syscond=1}
          written-local-variables:
            access WV_RRCCSW_FA_Init_write_IRV: accessed-variable=RRCCSW_FA_Init_write_IRV, variation-point={short-label=vpWV_RRCCSW_FA_Init_write_IRV, sw-syscond=1}
        FsftASLR_b_SpdLmtrOnOffSts: variation-point={short-label=vpFsftASLR_b_SpdLmtrOnOffSts, sw-syscond=1}
          written-local-variables:
            access WV_SpeedLimiterOnOffStsFA_write_IRV: accessed-variable=SpeedLimiterOnOffStsFA_write_IRV, variation-point={short-label=vpWV_SpeedLimiterOnOffStsFA_write_IRV, sw-syscond=1}
        FsftASLR_b_TSRSts: variation-point={short-label=vpFsftASLR_b_TSRSts, sw-syscond=1}
          written-local-variables:
            access WV_TSRStsFA_Init_write_IRV: accessed-variable=TSRStsFA_Init_write_IRV, variation-point={short-label=vpWV_TSRStsFA_Init_write_IRV, sw-syscond=1}
        PokeASLR_Init_EEPROM
        PokeASLR_b_LaneCenteringOnOffSts: variation-point={short-label=vpPokeASLR_b_LaneCenteringOnOffSts, sw-syscond=1}
          written-local-variables:
            access WV_LaneCenteringOnOffStsFA_write_IRV: accessed-variable=LaneCenteringOnOffStsFA_write_IRV, variation-point={short-label=vpWV_LaneCenteringOnOffStsFA_write_IRV, sw-syscond=1}
            access WV_LaneCenteringOnOffSts_write_IRV: accessed-variable=LaneCenteringOnOffSts_write_IRV, variation-point={short-label=vpWV_LaneCenteringOnOffSts_write_IRV, sw-syscond=1}
        PokeASLR_b_RRCCSw: variation-point={short-label=vpPokeASLR_b_RRCCSw, sw-syscond=1}
          written-local-variables:
            access WV_RRCCSW_FA_Init_write_IRV: accessed-variable=RRCCSW_FA_Init_write_IRV, variation-point={short-label=vpWV_RRCCSW_FA_Init_write_IRV, sw-syscond=1}
            access WV_RRCCSW_Init_write_IRV: accessed-variable=RRCCSW_Init_write_IRV, variation-point={short-label=vpWV_RRCCSW_Init_write_IRV, sw-syscond=1}
        PokeASLR_b_SignCaptMode: variation-point={short-label=vpPokeASLR_b_SignCaptMode, sw-syscond=1}
          written-local-variables:
            access WV_SignCaptureMode_write_IRV: accessed-variable=SignCaptureMode_write_IRV, variation-point={short-label=vpWV_SignCaptureMode_write_IRV, sw-syscond=1}
        PokeASLR_b_SpdLmtrOnOffSts: variation-point={short-label=vpPokeASLR_b_SpdLmtrOnOffSts, sw-syscond=1}
          written-local-variables:
            access WV_SpeedLimiterOnOffStsFA_write_IRV: accessed-variable=SpeedLimiterOnOffStsFA_write_IRV, variation-point={short-label=vpWV_SpeedLimiterOnOffStsFA_write_IRV, sw-syscond=1}
            access WV_SpeedLimiterOnOffSts_write_IRV: accessed-variable=SpeedLimiterOnOffSts_write_IRV, variation-point={short-label=vpWV_SpeedLimiterOnOffSts_write_IRV, sw-syscond=1}
        PokeASLR_b_TSR_Req: variation-point={short-label=vpPokeASLR_b_TSR_Req, sw-syscond=1}
          written-local-variables:
            access WV_TSR_Req_write_IRV: accessed-variable=TSR_Req_write_IRV, variation-point={short-label=vpWV_TSR_Req_write_IRV, sw-syscond=1}
        PokeASLR_e_DsplydSpdLimSts: variation-point={short-label=vpPokeASLR_e_DsplydSpdLimSts, sw-syscond=1}
          written-local-variables:
            access WV_DsplydSpdLimStsFA_Init_write_IRV: accessed-variable=DsplydSpdLimStsFA_Init_write_IRV, variation-point={short-label=vpWV_DsplydSpdLimStsFA_Init_write_IRV, sw-syscond=1}
            access WV_DisplayedSpeedLimSts_write_IRV: accessed-variable=DisplayedSpeedLimSts_write_IRV, variation-point={short-label=vpWV_DisplayedSpeedLimSts_write_IRV, sw-syscond=1}
        PokeASLR_e_Hill_Des_Status: variation-point={short-label=vpPokeASLR_e_Hill_Des_Status, sw-syscond=1}
          written-local-variables:
            access WV_HDC_FA_Init_write_IRV: accessed-variable=HDC_FA_Init_write_IRV, variation-point={short-label=vpWV_HDC_FA_Init_write_IRV, sw-syscond=1}
            access WV_Hill_Des_St_Init_write_IRV: accessed-variable=Hill_Des_St_Init_write_IRV, variation-point={short-label=vpWV_Hill_Des_St_Init_write_IRV, sw-syscond=1}
        PokeASLR_e_TSRSts: variation-point={short-label=vpPokeASLR_e_TSRSts, sw-syscond=1}
          written-local-variables:
            access WV_TSRStsFA_Init_write_IRV: accessed-variable=TSRStsFA_Init_write_IRV, variation-point={short-label=vpWV_TSRStsFA_Init_write_IRV, sw-syscond=1}
            access WV_TSRSts_write_IRV: accessed-variable=TSRSts_write_IRV, variation-point={short-label=vpWV_TSRSts_write_IRV, sw-syscond=1}
      variation point proxy Variant_ASLR_1: category=CONDITION, condition-access=0
      variation point proxy Variant_ASLR_3: category=CONDITION, condition-access=1
